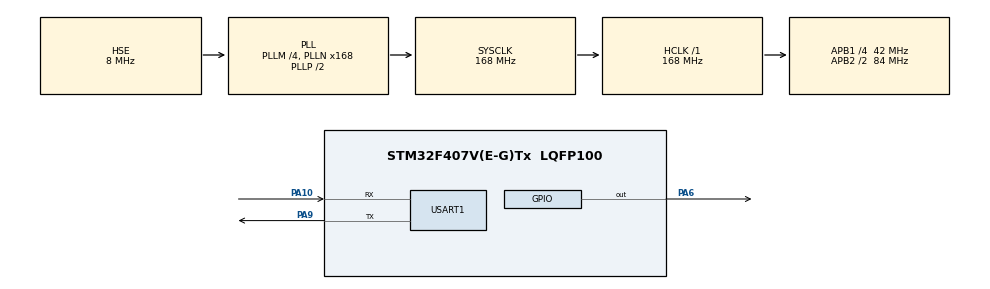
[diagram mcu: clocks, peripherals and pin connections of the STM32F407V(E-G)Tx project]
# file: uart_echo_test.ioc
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Mcu.Family=STM32F4
Mcu.Name=STM32F407V(E-G)Tx
Mcu.Package=LQFP100
NVIC.PriorityGroup=NVIC_PRIORITYGROUP_4
NVIC.USART1_IRQn=true\:0\:0\:false\:false\:true\:true\:true\:true
PA10.Mode=Asynchronous
PA10.Signal=USART1_RX
PA13.Mode=JTAG_5_pins
PA13.Signal=SYS_JTMS-SWDIO
PA14.Mode=JTAG_5_pins
PA14.Signal=SYS_JTCK-SWCLK
PA15.Mode=JTAG_5_pins
PA15.Signal=SYS_JTDI
PA6.GPIO_Speed=GPIO_SPEED_FREQ_LOW
PA6.PinState=GPIO_PIN_SET
PA6.Signal=GPIO_Output
PA9.Mode=Asynchronous
PA9.Signal=USART1_TX
PB3.Mode=JTAG_5_pins
PB3.Signal=SYS_JTDO-SWO
PB4.Mode=JTAG_5_pins
PB4.Signal=SYS_JTRST
PH0-OSC_IN.Mode=HSE-External-Oscillator
PH0-OSC_IN.Signal=RCC_OSC_IN
PH1-OSC_OUT.Mode=HSE-External-Oscillator
PH1-OSC_OUT.Signal=RCC_OSC_OUT
ProjectManager.HeapSize=0x200
ProjectManager.StackSize=0x400
ProjectManager.TargetToolchain=STM32CubeIDE
RCC.48MHZClocksFreq_Value=84000000
RCC.AHBFreq_Value=168000000
RCC.APB1CLKDivider=RCC_HCLK_DIV4
RCC.APB1Freq_Value=42000000
RCC.APB1TimFreq_Value=84000000
RCC.APB2CLKDivider=RCC_HCLK_DIV2
RCC.APB2Freq_Value=84000000
RCC.APB2TimFreq_Value=168000000
RCC.CortexFreq_Value=168000000
RCC.HCLKFreq_Value=168000000
RCC.HSE_VALUE=8000000
RCC.HSI_VALUE=16000000
RCC.LSE_VALUE=32768
RCC.PLLM=4
RCC.PLLN=168
RCC.PLLSourceVirtual=RCC_PLLSOURCE_HSE
RCC.SYSCLKFreq_VALUE=168000000
RCC.SYSCLKSource=RCC_SYSCLKSOURCE_PLLCLK
RCC.VCOOutputFreq_Value=336000000
USART1.VirtualMode=VM_ASYNC
board=custom

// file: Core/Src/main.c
/* USER CODE BEGIN Header */
/**
  ******************************************************************************
  * @file           : main.c
  * @brief          : Main program body
  ******************************************************************************
  * @attention
  *
  * Copyright (c) 2025 STMicroelectronics.
  * All rights reserved.
  *
  * This software is licensed under terms that can be found in the LICENSE file
  * in the root directory of this software component.
  * If no LICENSE file comes with this software, it is provided AS-IS.
  *
  ******************************************************************************
  */
/* USER CODE END Header */
#include "main.h"
#include "uart.h"

/* USER CODE BEGIN PTD */

typedef struct _COUNTERS
{
	uint32_t ledOffCnt;
	uint32_t ledOnCnt;
} COUNTERS;

typedef struct _FLAGS
{
	uint32_t isLedOn : 1;
	uint32_t reserv  : 31;
} FLAGS;

/* USER CODE END PTD */

/* USER CODE BEGIN PD */
#define LED_DISABLE()  HAL_GPIO_WritePin(GPIOA, GPIO_PIN_6, GPIO_PIN_SET);
#define LED_ENABLE()   HAL_GPIO_WritePin(GPIOA, GPIO_PIN_6, GPIO_PIN_RESET);

#define LED_ON_TIME_MS 100
#define LED_OFF_TIME_MS 100
/* USER CODE END PD */

extern UART_HandleTypeDef huart1;

uint8_t ledEnable = 0;
COUNTERS counters = {0};
FLAGS flags = {0};

void SystemClock_Config(void);
static void MX_GPIO_Init(void);
void led_blink(void);

int main(void)
{

  /* MCU Configuration--------------------------------------------------------*/

  /* Reset of all peripherals, Initializes the Flash interface and the Systick. */
  HAL_Init();

  /* Configure the system clock */
  SystemClock_Config();

  /* USER CODE BEGIN SysInit */
  counters.ledOffCnt = HAL_GetTick();
  counters.ledOnCnt = HAL_GetTick();
  /* USER CODE END SysInit */

  /* Initialize all configured peripherals */
  MX_GPIO_Init();
  MX_USART1_UART_Init();

  /* Infinite loop */
  /* USER CODE BEGIN WHILE */
  while (1)
  {
	  uart_main(&ledEnable);
	  led_blink();
    /* USER CODE END WHILE */

  }
}

void SystemClock_Config(void)
{
  RCC_OscInitTypeDef RCC_OscInitStruct = {0};
  RCC_ClkInitTypeDef RCC_ClkInitStruct = {0};

  /** Configure the main internal regulator output voltage
  */
  __HAL_RCC_PWR_CLK_ENABLE();
  __HAL_PWR_VOLTAGESCALING_CONFIG(PWR_REGULATOR_VOLTAGE_SCALE1);

  /** Initializes the RCC Oscillators according to the specified parameters
  * in the RCC_OscInitTypeDef structure.
  */
  RCC_OscInitStruct.OscillatorType = RCC_OSCILLATORTYPE_HSE;
  RCC_OscInitStruct.HSEState = RCC_HSE_ON;
  RCC_OscInitStruct.PLL.PLLState = RCC_PLL_ON;
  RCC_OscInitStruct.PLL.PLLSource = RCC_PLLSOURCE_HSE;
  RCC_OscInitStruct.PLL.PLLM = 4;
  RCC_OscInitStruct.PLL.PLLN = 168;
  RCC_OscInitStruct.PLL.PLLP = RCC_PLLP_DIV2;
  RCC_OscInitStruct.PLL.PLLQ = 4;
  if (HAL_RCC_OscConfig(&RCC_OscInitStruct) != HAL_OK)
  {
    Error_Handler();
  }

  /** Initializes the CPU, AHB and APB buses clocks
  */
  RCC_ClkInitStruct.ClockType = RCC_CLOCKTYPE_HCLK|RCC_CLOCKTYPE_SYSCLK
                              |RCC_CLOCKTYPE_PCLK1|RCC_CLOCKTYPE_PCLK2;
  RCC_ClkInitStruct.SYSCLKSource = RCC_SYSCLKSOURCE_PLLCLK;
  RCC_ClkInitStruct.AHBCLKDivider = RCC_SYSCLK_DIV1;
  RCC_ClkInitStruct.APB1CLKDivider = RCC_HCLK_DIV4;
  RCC_ClkInitStruct.APB2CLKDivider = RCC_HCLK_DIV2;

  if (HAL_RCC_ClockConfig(&RCC_ClkInitStruct, FLASH_LATENCY_5) != HAL_OK)
  {
    Error_Handler();
  }
}

void led_blink(void)
{
	if ( ledEnable )
	{
		if ( flags.isLedOn == 0 )
		{
			if ( HAL_GetTick() - counters.ledOffCnt > LED_OFF_TIME_MS )
			{
				counters.ledOnCnt = HAL_GetTick();
				LED_ENABLE();
				flags.isLedOn = 1;
			}
		} else if ( HAL_GetTick() - counters.ledOnCnt > LED_ON_TIME_MS )
		{
			counters.ledOffCnt = HAL_GetTick();
			LED_DISABLE();
			flags.isLedOn = 0;
		}
	}
	else
	{
		LED_DISABLE();
	}
}

static void MX_GPIO_Init(void)
{
  GPIO_InitTypeDef GPIO_InitStruct = {0};

  /* GPIO Ports Clock Enable */
  __HAL_RCC_GPIOH_CLK_ENABLE();
  __HAL_RCC_GPIOA_CLK_ENABLE();
  __HAL_RCC_GPIOB_CLK_ENABLE();

  /*Configure GPIO pin Output Level */
  LED_DISABLE();

  /*Configure GPIO pin : PA6 */
  GPIO_InitStruct.Pin = GPIO_PIN_6;
  GPIO_InitStruct.Mode = GPIO_MODE_OUTPUT_PP;
  GPIO_InitStruct.Pull = GPIO_NOPULL;
  GPIO_InitStruct.Speed = GPIO_SPEED_FREQ_LOW;
  HAL_GPIO_Init(GPIOA, &GPIO_InitStruct);

}

void Error_Handler(void)
{
  __disable_irq();
  while (1)
  {
  }
}
